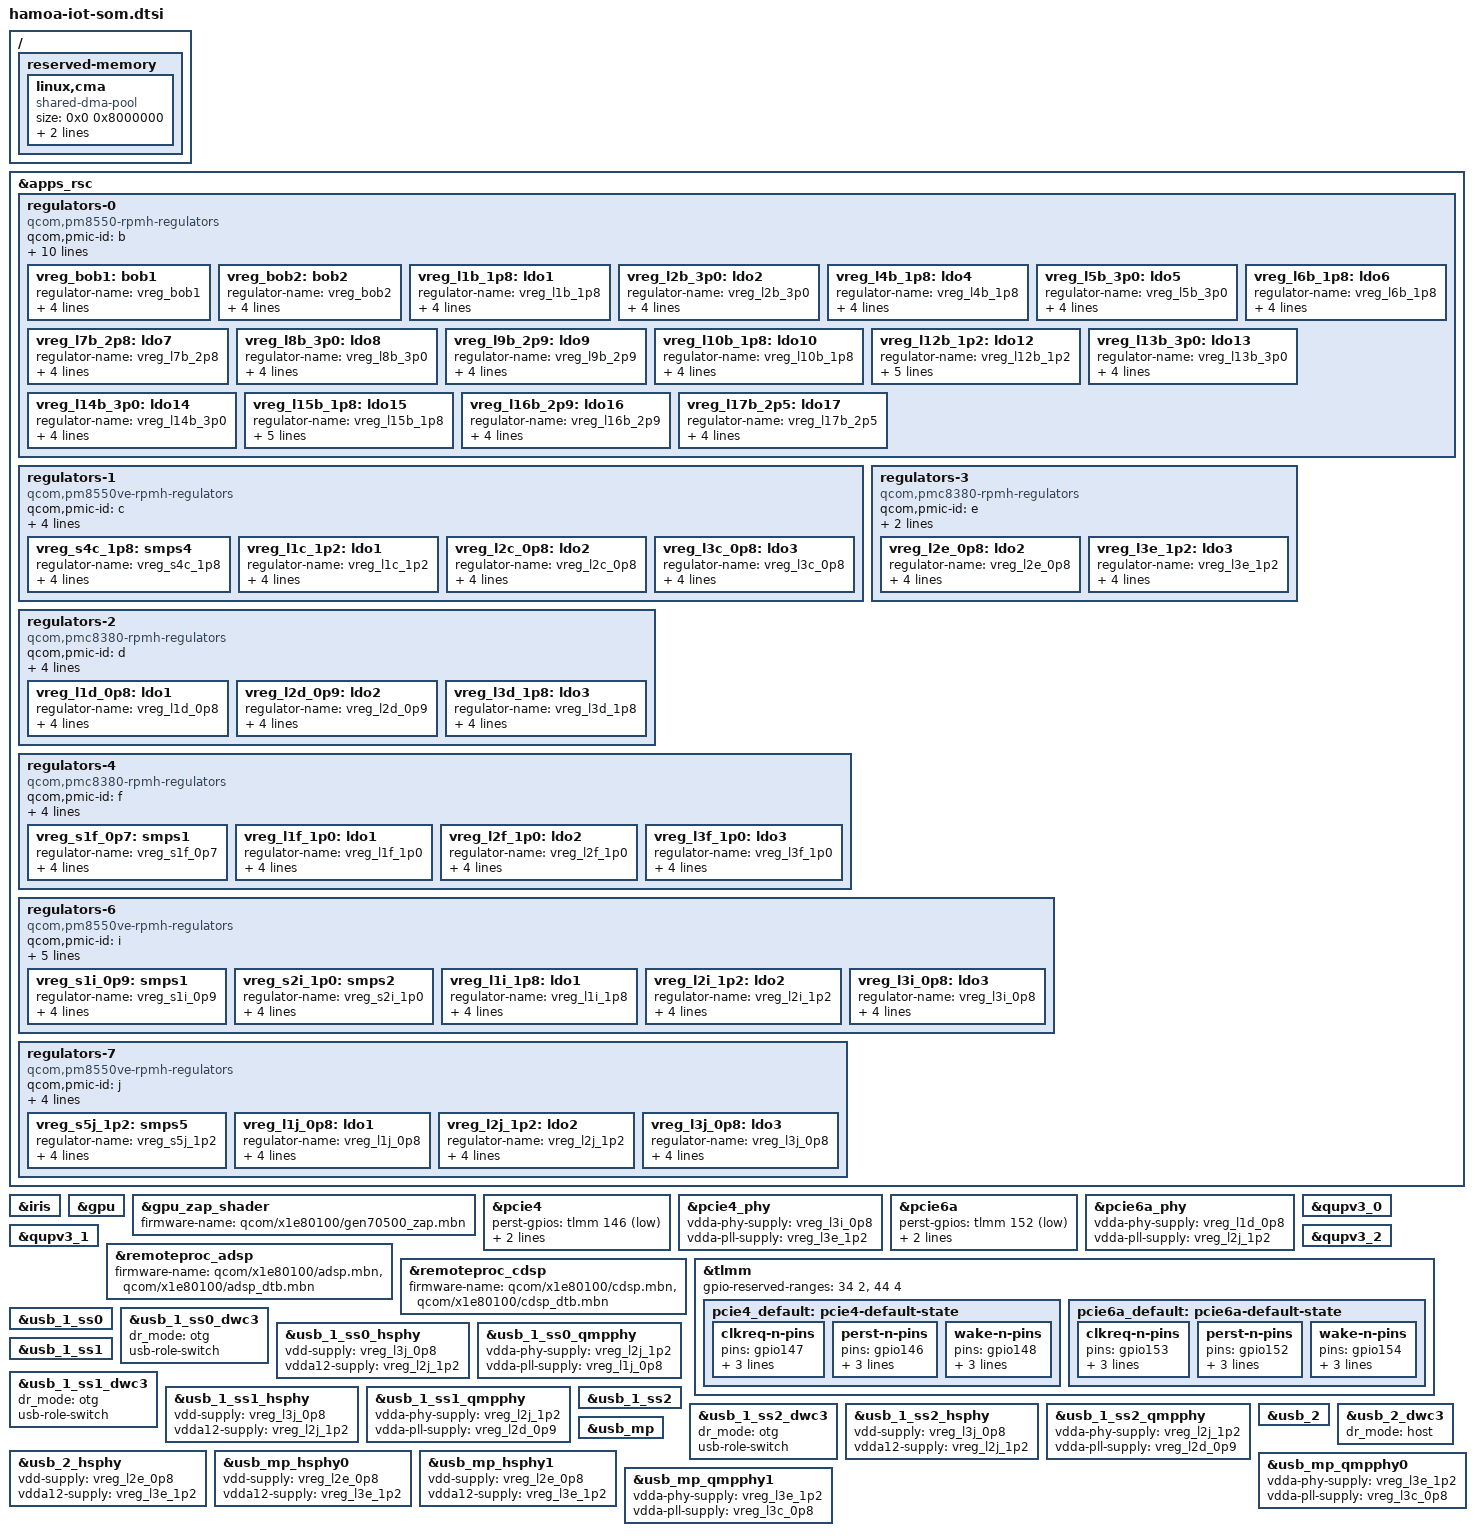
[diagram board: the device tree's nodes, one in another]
// SPDX-License-Identifier: BSD-3-Clause
/*
 * Copyright (c) Qualcomm Technologies, Inc. and/or its subsidiaries.
 */

#include "x1e80100.dtsi"
#include "x1e80100-pmics.dtsi"
#include <dt-bindings/gpio/gpio.h>
#include <dt-bindings/regulator/qcom,rpmh-regulator.h>

/ {
	reserved-memory {
		linux,cma {
			compatible = "shared-dma-pool";
			size = <0x0 0x8000000>;
			reusable;
			linux,cma-default;
		};
	};
};

&apps_rsc {
	/* PMC8380C_B */
	regulators-0 {
		compatible = "qcom,pm8550-rpmh-regulators";
		qcom,pmic-id = "b";

		vdd-bob1-supply = <&vph_pwr>;
		vdd-bob2-supply = <&vph_pwr>;
		vdd-l1-l4-l10-supply = <&vreg_s4c_1p8>;
		vdd-l2-l13-l14-supply = <&vreg_bob1>;
		vdd-l5-l16-supply = <&vreg_bob1>;
		vdd-l6-l7-supply = <&vreg_bob2>;
		vdd-l8-l9-supply = <&vreg_bob1>;
		vdd-l12-supply = <&vreg_s5j_1p2>;
		vdd-l15-supply = <&vreg_s4c_1p8>;
		vdd-l17-supply = <&vreg_bob2>;

		vreg_bob1: bob1 {
			regulator-name = "vreg_bob1";
			regulator-min-microvolt = <3008000>;
			regulator-max-microvolt = <3960000>;
			regulator-initial-mode = <RPMH_REGULATOR_MODE_HPM>;
		};

		vreg_bob2: bob2 {
			regulator-name = "vreg_bob2";
			regulator-min-microvolt = <2504000>;
			regulator-max-microvolt = <3008000>;
			regulator-initial-mode = <RPMH_REGULATOR_MODE_HPM>;
		};

		vreg_l1b_1p8: ldo1 {
			regulator-name = "vreg_l1b_1p8";
			regulator-min-microvolt = <1800000>;
			regulator-max-microvolt = <1800000>;
			regulator-initial-mode = <RPMH_REGULATOR_MODE_HPM>;
		};

		vreg_l2b_3p0: ldo2 {
			regulator-name = "vreg_l2b_3p0";
			regulator-min-microvolt = <3072000>;
			regulator-max-microvolt = <3100000>;
			regulator-initial-mode = <RPMH_REGULATOR_MODE_HPM>;
		};

		vreg_l4b_1p8: ldo4 {
			regulator-name = "vreg_l4b_1p8";
			regulator-min-microvolt = <1800000>;
			regulator-max-microvolt = <1800000>;
			regulator-initial-mode = <RPMH_REGULATOR_MODE_HPM>;
		};

		vreg_l5b_3p0: ldo5 {
			regulator-name = "vreg_l5b_3p0";
			regulator-min-microvolt = <3000000>;
			regulator-max-microvolt = <3000000>;
			regulator-initial-mode = <RPMH_REGULATOR_MODE_HPM>;
		};

		vreg_l6b_1p8: ldo6 {
			regulator-name = "vreg_l6b_1p8";
			regulator-min-microvolt = <1800000>;
			regulator-max-microvolt = <2960000>;
			regulator-initial-mode = <RPMH_REGULATOR_MODE_HPM>;
		};

		vreg_l7b_2p8: ldo7 {
			regulator-name = "vreg_l7b_2p8";
			regulator-min-microvolt = <2800000>;
			regulator-max-microvolt = <2800000>;
			regulator-initial-mode = <RPMH_REGULATOR_MODE_HPM>;
		};

		vreg_l8b_3p0: ldo8 {
			regulator-name = "vreg_l8b_3p0";
			regulator-min-microvolt = <3072000>;
			regulator-max-microvolt = <3072000>;
			regulator-initial-mode = <RPMH_REGULATOR_MODE_HPM>;
		};

		vreg_l9b_2p9: ldo9 {
			regulator-name = "vreg_l9b_2p9";
			regulator-min-microvolt = <2960000>;
			regulator-max-microvolt = <2960000>;
			regulator-initial-mode = <RPMH_REGULATOR_MODE_HPM>;
		};

		vreg_l10b_1p8: ldo10 {
			regulator-name = "vreg_l10b_1p8";
			regulator-min-microvolt = <1800000>;
			regulator-max-microvolt = <1800000>;
			regulator-initial-mode = <RPMH_REGULATOR_MODE_HPM>;
		};

		vreg_l12b_1p2: ldo12 {
			regulator-name = "vreg_l12b_1p2";
			regulator-min-microvolt = <1200000>;
			regulator-max-microvolt = <1200000>;
			regulator-initial-mode = <RPMH_REGULATOR_MODE_HPM>;
			regulator-always-on;
		};

		vreg_l13b_3p0: ldo13 {
			regulator-name = "vreg_l13b_3p0";
			regulator-min-microvolt = <3072000>;
			regulator-max-microvolt = <3100000>;
			regulator-initial-mode = <RPMH_REGULATOR_MODE_HPM>;
		};

		vreg_l14b_3p0: ldo14 {
			regulator-name = "vreg_l14b_3p0";
			regulator-min-microvolt = <3072000>;
			regulator-max-microvolt = <3072000>;
			regulator-initial-mode = <RPMH_REGULATOR_MODE_HPM>;
		};

		vreg_l15b_1p8: ldo15 {
			regulator-name = "vreg_l15b_1p8";
			regulator-min-microvolt = <1800000>;
			regulator-max-microvolt = <1800000>;
			regulator-initial-mode = <RPMH_REGULATOR_MODE_HPM>;
			regulator-always-on;
		};

		vreg_l16b_2p9: ldo16 {
			regulator-name = "vreg_l16b_2p9";
			regulator-min-microvolt = <2912000>;
			regulator-max-microvolt = <2912000>;
			regulator-initial-mode = <RPMH_REGULATOR_MODE_HPM>;
		};

		vreg_l17b_2p5: ldo17 {
			regulator-name = "vreg_l17b_2p5";
			regulator-min-microvolt = <2504000>;
			regulator-max-microvolt = <2504000>;
			regulator-initial-mode = <RPMH_REGULATOR_MODE_HPM>;
		};
	};

	/* PMC8380VE_C */
	regulators-1 {
		compatible = "qcom,pm8550ve-rpmh-regulators";
		qcom,pmic-id = "c";

		vdd-l1-supply = <&vreg_s5j_1p2>;
		vdd-l2-supply = <&vreg_s1f_0p7>;
		vdd-l3-supply = <&vreg_s1f_0p7>;
		vdd-s4-supply = <&vph_pwr>;

		vreg_s4c_1p8: smps4 {
			regulator-name = "vreg_s4c_1p8";
			regulator-min-microvolt = <1856000>;
			regulator-max-microvolt = <2000000>;
			regulator-initial-mode = <RPMH_REGULATOR_MODE_HPM>;
		};

		vreg_l1c_1p2: ldo1 {
			regulator-name = "vreg_l1c_1p2";
			regulator-min-microvolt = <1200000>;
			regulator-max-microvolt = <1200000>;
			regulator-initial-mode = <RPMH_REGULATOR_MODE_HPM>;
		};

		vreg_l2c_0p8: ldo2 {
			regulator-name = "vreg_l2c_0p8";
			regulator-min-microvolt = <880000>;
			regulator-max-microvolt = <920000>;
			regulator-initial-mode = <RPMH_REGULATOR_MODE_HPM>;
		};

		vreg_l3c_0p8: ldo3 {
			regulator-name = "vreg_l3c_0p8";
			regulator-min-microvolt = <880000>;
			regulator-max-microvolt = <920000>;
			regulator-initial-mode = <RPMH_REGULATOR_MODE_HPM>;
		};
	};

	/* PMC8380_D */
	regulators-2 {
		compatible = "qcom,pmc8380-rpmh-regulators";
		qcom,pmic-id = "d";

		vdd-l1-supply = <&vreg_s1f_0p7>;
		vdd-l2-supply = <&vreg_s1f_0p7>;
		vdd-l3-supply = <&vreg_s4c_1p8>;
		vdd-s1-supply = <&vph_pwr>;

		vreg_l1d_0p8: ldo1 {
			regulator-name = "vreg_l1d_0p8";
			regulator-min-microvolt = <880000>;
			regulator-max-microvolt = <920000>;
			regulator-initial-mode = <RPMH_REGULATOR_MODE_HPM>;
		};

		vreg_l2d_0p9: ldo2 {
			regulator-name = "vreg_l2d_0p9";
			regulator-min-microvolt = <912000>;
			regulator-max-microvolt = <920000>;
			regulator-initial-mode = <RPMH_REGULATOR_MODE_HPM>;
		};

		vreg_l3d_1p8: ldo3 {
			regulator-name = "vreg_l3d_1p8";
			regulator-min-microvolt = <1800000>;
			regulator-max-microvolt = <1800000>;
			regulator-initial-mode = <RPMH_REGULATOR_MODE_HPM>;
		};
	};

	/* PMC8380_E */
	regulators-3 {
		compatible = "qcom,pmc8380-rpmh-regulators";
		qcom,pmic-id = "e";

		vdd-l2-supply = <&vreg_s1f_0p7>;
		vdd-l3-supply = <&vreg_s5j_1p2>;

		vreg_l2e_0p8: ldo2 {
			regulator-name = "vreg_l2e_0p8";
			regulator-min-microvolt = <880000>;
			regulator-max-microvolt = <920000>;
			regulator-initial-mode = <RPMH_REGULATOR_MODE_HPM>;
		};

		vreg_l3e_1p2: ldo3 {
			regulator-name = "vreg_l3e_1p2";
			regulator-min-microvolt = <1200000>;
			regulator-max-microvolt = <1200000>;
			regulator-initial-mode = <RPMH_REGULATOR_MODE_HPM>;
		};
	};

	/* PMC8380_F */
	regulators-4 {
		compatible = "qcom,pmc8380-rpmh-regulators";
		qcom,pmic-id = "f";

		vdd-l1-supply = <&vreg_s5j_1p2>;
		vdd-l2-supply = <&vreg_s5j_1p2>;
		vdd-l3-supply = <&vreg_s5j_1p2>;
		vdd-s1-supply = <&vph_pwr>;

		vreg_s1f_0p7: smps1 {
			regulator-name = "vreg_s1f_0p7";
			regulator-min-microvolt = <700000>;
			regulator-max-microvolt = <1100000>;
			regulator-initial-mode = <RPMH_REGULATOR_MODE_HPM>;
		};

		vreg_l1f_1p0: ldo1 {
			regulator-name = "vreg_l1f_1p0";
			regulator-min-microvolt = <1024000>;
			regulator-max-microvolt = <1024000>;
			regulator-initial-mode = <RPMH_REGULATOR_MODE_HPM>;
		};

		vreg_l2f_1p0: ldo2 {
			regulator-name = "vreg_l2f_1p0";
			regulator-min-microvolt = <1024000>;
			regulator-max-microvolt = <1024000>;
			regulator-initial-mode = <RPMH_REGULATOR_MODE_HPM>;
		};

		vreg_l3f_1p0: ldo3 {
			regulator-name = "vreg_l3f_1p0";
			regulator-min-microvolt = <1024000>;
			regulator-max-microvolt = <1024000>;
			regulator-initial-mode = <RPMH_REGULATOR_MODE_HPM>;
		};
	};

	/* PMC8380VE_I */
	regulators-6 {
		compatible = "qcom,pm8550ve-rpmh-regulators";
		qcom,pmic-id = "i";

		vdd-l1-supply = <&vreg_s4c_1p8>;
		vdd-l2-supply = <&vreg_s5j_1p2>;
		vdd-l3-supply = <&vreg_s1f_0p7>;
		vdd-s1-supply = <&vph_pwr>;
		vdd-s2-supply = <&vph_pwr>;

		vreg_s1i_0p9: smps1 {
			regulator-name = "vreg_s1i_0p9";
			regulator-min-microvolt = <900000>;
			regulator-max-microvolt = <920000>;
			regulator-initial-mode = <RPMH_REGULATOR_MODE_HPM>;
		};

		vreg_s2i_1p0: smps2 {
			regulator-name = "vreg_s2i_1p0";
			regulator-min-microvolt = <1000000>;
			regulator-max-microvolt = <1100000>;
			regulator-initial-mode = <RPMH_REGULATOR_MODE_HPM>;
		};

		vreg_l1i_1p8: ldo1 {
			regulator-name = "vreg_l1i_1p8";
			regulator-min-microvolt = <1800000>;
			regulator-max-microvolt = <1800000>;
			regulator-initial-mode = <RPMH_REGULATOR_MODE_HPM>;
		};

		vreg_l2i_1p2: ldo2 {
			regulator-name = "vreg_l2i_1p2";
			regulator-min-microvolt = <1200000>;
			regulator-max-microvolt = <1200000>;
			regulator-initial-mode = <RPMH_REGULATOR_MODE_HPM>;
		};

		vreg_l3i_0p8: ldo3 {
			regulator-name = "vreg_l3i_0p8";
			regulator-min-microvolt = <880000>;
			regulator-max-microvolt = <920000>;
			regulator-initial-mode = <RPMH_REGULATOR_MODE_HPM>;
		};
	};

	/* PMC8380VE_J */
	regulators-7 {
		compatible = "qcom,pm8550ve-rpmh-regulators";
		qcom,pmic-id = "j";

		vdd-l1-supply = <&vreg_s1f_0p7>;
		vdd-l2-supply = <&vreg_s5j_1p2>;
		vdd-l3-supply = <&vreg_s1f_0p7>;
		vdd-s5-supply = <&vph_pwr>;

		vreg_s5j_1p2: smps5 {
			regulator-name = "vreg_s5j_1p2";
			regulator-min-microvolt = <1256000>;
			regulator-max-microvolt = <1304000>;
			regulator-initial-mode = <RPMH_REGULATOR_MODE_HPM>;
		};

		vreg_l1j_0p8: ldo1 {
			regulator-name = "vreg_l1j_0p8";
			regulator-min-microvolt = <880000>;
			regulator-max-microvolt = <920000>;
			regulator-initial-mode = <RPMH_REGULATOR_MODE_HPM>;
		};

		vreg_l2j_1p2: ldo2 {
			regulator-name = "vreg_l2j_1p2";
			regulator-min-microvolt = <1256000>;
			regulator-max-microvolt = <1256000>;
			regulator-initial-mode = <RPMH_REGULATOR_MODE_HPM>;
		};

		vreg_l3j_0p8: ldo3 {
			regulator-name = "vreg_l3j_0p8";
			regulator-min-microvolt = <880000>;
			regulator-max-microvolt = <920000>;
			regulator-initial-mode = <RPMH_REGULATOR_MODE_HPM>;
		};
	};
};

&iris {
	status = "okay";
};

&gpu {
	status = "okay";
};

&gpu_zap_shader {
	firmware-name = "qcom/x1e80100/gen70500_zap.mbn";
};

&pcie4 {
	perst-gpios = <&tlmm 146 GPIO_ACTIVE_LOW>;
	wake-gpios = <&tlmm 148 GPIO_ACTIVE_LOW>;

	pinctrl-0 = <&pcie4_default>;
	pinctrl-names = "default";

	status = "okay";
};

&pcie4_phy {
	vdda-phy-supply = <&vreg_l3i_0p8>;
	vdda-pll-supply = <&vreg_l3e_1p2>;

	status = "okay";
};

&pcie6a {
	perst-gpios = <&tlmm 152 GPIO_ACTIVE_LOW>;
	wake-gpios = <&tlmm 154 GPIO_ACTIVE_LOW>;

	pinctrl-0 = <&pcie6a_default>;
	pinctrl-names = "default";

	status = "okay";
};

&pcie6a_phy {
	vdda-phy-supply = <&vreg_l1d_0p8>;
	vdda-pll-supply = <&vreg_l2j_1p2>;

	status = "okay";
};

&qupv3_0 {
	status = "okay";
};

&qupv3_1 {
	status = "okay";
};

&qupv3_2 {
	status = "okay";
};

&remoteproc_adsp {
	firmware-name = "qcom/x1e80100/adsp.mbn",
			"qcom/x1e80100/adsp_dtb.mbn";

	status = "okay";
};

&remoteproc_cdsp {
	firmware-name = "qcom/x1e80100/cdsp.mbn",
			"qcom/x1e80100/cdsp_dtb.mbn";

	status = "okay";
};

&tlmm {
	gpio-reserved-ranges = <34 2>, /* TPM LP & INT */
			       <44 4>; /* SPI (TPM) */

	pcie4_default: pcie4-default-state {
		clkreq-n-pins {
			pins = "gpio147";
			function = "pcie4_clk";
			drive-strength = <2>;
			bias-pull-up;
		};

		perst-n-pins {
			pins = "gpio146";
			function = "gpio";
			drive-strength = <2>;
			bias-disable;
		};

		wake-n-pins {
			pins = "gpio148";
			function = "gpio";
			drive-strength = <2>;
			bias-pull-up;
		};
	};

	pcie6a_default: pcie6a-default-state {
		clkreq-n-pins {
			pins = "gpio153";
			function = "pcie6a_clk";
			drive-strength = <2>;
			bias-pull-up;
		};

		perst-n-pins {
			pins = "gpio152";
			function = "gpio";
			drive-strength = <2>;
			bias-disable;
		};

		wake-n-pins {
			pins = "gpio154";
			function = "gpio";
			drive-strength = <2>;
			bias-pull-up;

		};
	};
};

&usb_1_ss0 {
	status = "okay";
};

&usb_1_ss0_dwc3 {
	dr_mode = "otg";
	usb-role-switch;
};

&usb_1_ss0_hsphy {
	vdd-supply = <&vreg_l3j_0p8>;
	vdda12-supply = <&vreg_l2j_1p2>;

	status = "okay";
};

&usb_1_ss0_qmpphy {
	vdda-phy-supply = <&vreg_l2j_1p2>;
	vdda-pll-supply = <&vreg_l1j_0p8>;

	status = "okay";
};

&usb_1_ss1 {
	status = "okay";
};

&usb_1_ss1_dwc3 {
	dr_mode = "otg";
	usb-role-switch;
};

&usb_1_ss1_hsphy {
	vdd-supply = <&vreg_l3j_0p8>;
	vdda12-supply = <&vreg_l2j_1p2>;

	status = "okay";
};

&usb_1_ss1_qmpphy {
	vdda-phy-supply = <&vreg_l2j_1p2>;
	vdda-pll-supply = <&vreg_l2d_0p9>;

	status = "okay";
};

&usb_1_ss2 {
	status = "okay";
};

&usb_1_ss2_dwc3 {
	dr_mode = "otg";
	usb-role-switch;
};

&usb_1_ss2_hsphy {
	vdd-supply = <&vreg_l3j_0p8>;
	vdda12-supply = <&vreg_l2j_1p2>;

	status = "okay";
};

&usb_1_ss2_qmpphy {
	vdda-phy-supply = <&vreg_l2j_1p2>;
	vdda-pll-supply = <&vreg_l2d_0p9>;

	status = "okay";
};

&usb_2 {
	status = "okay";
};

&usb_2_dwc3 {
	dr_mode = "host";
};

&usb_2_hsphy {
	vdd-supply = <&vreg_l2e_0p8>;
	vdda12-supply = <&vreg_l3e_1p2>;

	status = "okay";
};

&usb_mp {
	status = "okay";
};

&usb_mp_hsphy0 {
	vdd-supply = <&vreg_l2e_0p8>;
	vdda12-supply = <&vreg_l3e_1p2>;

	status = "okay";
};

&usb_mp_hsphy1 {
	vdd-supply = <&vreg_l2e_0p8>;
	vdda12-supply = <&vreg_l3e_1p2>;

	status = "okay";
};

&usb_mp_qmpphy0 {
	vdda-phy-supply = <&vreg_l3e_1p2>;
	vdda-pll-supply = <&vreg_l3c_0p8>;

	status = "okay";
};

&usb_mp_qmpphy1 {
	vdda-phy-supply = <&vreg_l3e_1p2>;
	vdda-pll-supply = <&vreg_l3c_0p8>;

	status = "okay";
};
